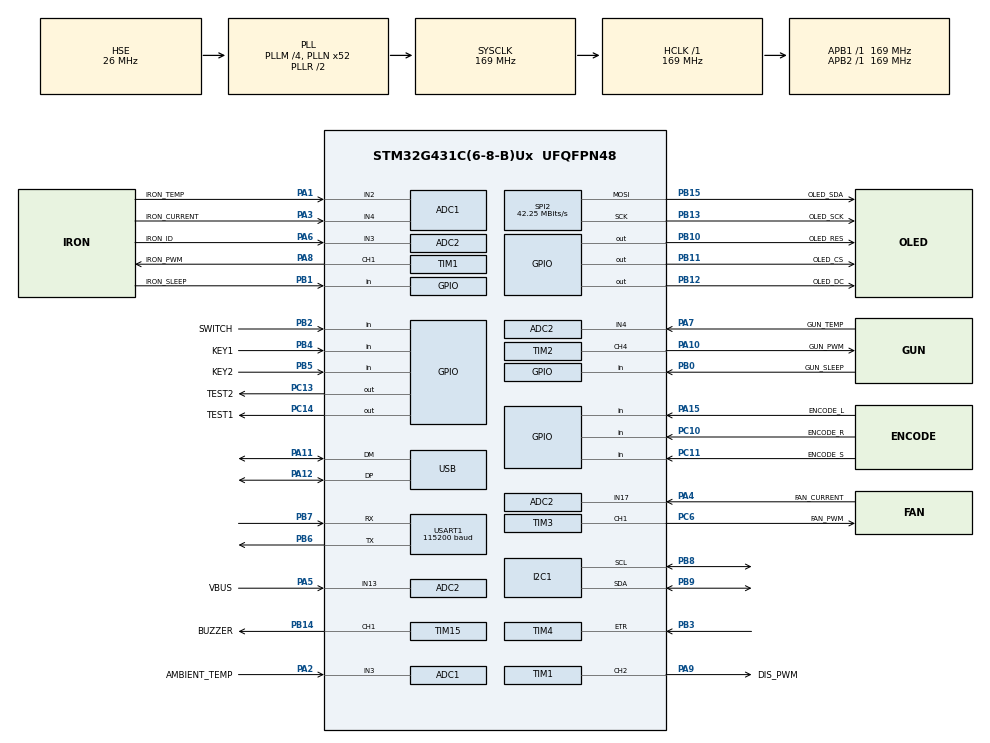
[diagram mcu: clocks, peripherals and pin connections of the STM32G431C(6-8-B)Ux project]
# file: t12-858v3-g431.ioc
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ADC1.EnableInjectedConversion=ENABLE
ADC1.EnableInjectedOversampling=DISABLE
ADC1.EnableRegularConversion=DISABLE
ADC1.ExternalTrigInjecConv=ADC_EXTERNALTRIGINJEC_T1_TRGO
ADC1.ExternalTrigInjecConvEdge=ADC_EXTERNALTRIGINJECCONV_EDGE_FALLING
ADC1.InjNumberOfConversion=2
ADC1.InjectedChannel-2\#ChannelInjectedConversion=ADC_CHANNEL_2
ADC1.InjectedChannel-3\#ChannelInjectedConversion=ADC_CHANNEL_4
ADC1.InjectedConvMode=None
ADC1.InjectedOffsetNumber-2\#ChannelInjectedConversion=ADC_OFFSET_NONE
ADC1.InjectedOffsetNumber-3\#ChannelInjectedConversion=ADC_OFFSET_NONE
ADC1.InjectedRank-2\#ChannelInjectedConversion=1
ADC1.InjectedRank-3\#ChannelInjectedConversion=2
ADC1.InjectedSamplingTime-2\#ChannelInjectedConversion=ADC_SAMPLETIME_12CYCLES_5
ADC1.InjectedSamplingTime-3\#ChannelInjectedConversion=ADC_SAMPLETIME_2CYCLES_5
ADC1.Rank2_Channel=ADC_CHANNEL_4
ADC1.injectedQueueMode=DISABLE
ADC1.master=1
ADC2.EnableInjectedConversion=ENABLE
ADC2.EnableRegularConversion=DISABLE
ADC2.ExternalTrigInjecConv=ADC_EXTERNALTRIGINJEC_T1_TRGO
ADC2.ExternalTrigInjecConvEdge=ADC_EXTERNALTRIGINJECCONV_EDGE_FALLING
ADC2.InjNumberOfConversion=2
ADC2.InjectedChannel-1\#ChannelInjectedConversion=ADC_CHANNEL_4
ADC2.InjectedChannel-2\#ChannelInjectedConversion=ADC_CHANNEL_17
ADC2.InjectedOffsetNumber-1\#ChannelInjectedConversion=ADC_OFFSET_NONE
ADC2.InjectedOffsetNumber-2\#ChannelInjectedConversion=ADC_OFFSET_NONE
ADC2.InjectedRank-1\#ChannelInjectedConversion=1
ADC2.InjectedRank-2\#ChannelInjectedConversion=2
ADC2.InjectedSamplingTime-1\#ChannelInjectedConversion=ADC_SAMPLETIME_12CYCLES_5
ADC2.InjectedSamplingTime-2\#ChannelInjectedConversion=ADC_SAMPLETIME_2CYCLES_5
ADC2.Rank2_Channel=ADC_CHANNEL_17
Dma.Request0=SPI2_TX
Dma.SPI2_TX.0.Direction=DMA_MEMORY_TO_PERIPH
Dma.SPI2_TX.0.EventEnable=DISABLE
Dma.SPI2_TX.0.Instance=DMA1_Channel1
Dma.SPI2_TX.0.MemDataAlignment=DMA_MDATAALIGN_BYTE
Dma.SPI2_TX.0.MemInc=DMA_MINC_ENABLE
Dma.SPI2_TX.0.Mode=DMA_NORMAL
Dma.SPI2_TX.0.PeriphDataAlignment=DMA_PDATAALIGN_BYTE
Dma.SPI2_TX.0.PeriphInc=DMA_PINC_DISABLE
Dma.SPI2_TX.0.Polarity=HAL_DMAMUX_REQ_GEN_RISING
Dma.SPI2_TX.0.Priority=DMA_PRIORITY_HIGH
Dma.SPI2_TX.0.RequestNumber=1
Dma.SPI2_TX.0.SignalID=NONE
Dma.SPI2_TX.0.SyncEnable=DISABLE
Dma.SPI2_TX.0.SyncPolarity=HAL_DMAMUX_SYNC_NO_EVENT
Dma.SPI2_TX.0.SyncRequestNumber=1
Dma.SPI2_TX.0.SyncSignalID=NONE
I2C1.Timing=0x408086C6
Mcu.Family=STM32G4
Mcu.Name=STM32G431C(6-8-B)Ux
Mcu.Package=UFQFPN48
NVIC.ADC1_2_IRQn=true\:0\:0\:false\:false\:true\:true\:true\:true
NVIC.DMA1_Channel1_IRQn=true\:0\:0\:false\:false\:true\:false\:true\:true
NVIC.PriorityGroup=NVIC_PRIORITYGROUP_4
NVIC.TIM3_IRQn=true\:0\:0\:false\:false\:true\:true\:true\:true
OPAMP1.PowerMode=OPAMP_POWERMODE_HIGHSPEED
PA1.GPIO_Label=IRON_TEMP
PA1.Signal=SharedAnalog_PA1
PA10.GPIO_Label=GUN_PWM
PA10.Signal=S_TIM2_CH4
PA11.Mode=Device
PA11.Signal=USB_DM
PA12.Mode=Device
PA12.Signal=USB_DP
PA13.Mode=Serial_Wire
PA13.Signal=SYS_JTMS-SWDIO
PA14.Mode=Serial_Wire
PA14.Signal=SYS_JTCK-SWCLK
PA15.GPIO_Label=ENCODE_L
PA15.GPIO_PuPd=GPIO_PULLUP
PA15.Signal=GPIO_Input
PA2.GPIO_Label=AMBIENT_TEMP
PA2.Mode=IN3-Single-Ended
PA2.Signal=ADC1_IN3
PA3.GPIO_Label=IRON_CURRENT
PA3.Mode=IN4-Single-Ended
PA3.Signal=ADC1_IN4
PA4.GPIO_Label=FAN_CURRENT
PA4.Mode=IN17-Single-Ended
PA4.Signal=ADC2_IN17
PA5.GPIO_Label=VBUS
PA5.Mode=IN13-Single-Ended
PA5.Signal=ADC2_IN13
PA6.GPIO_Label=IRON_ID
PA6.Mode=IN3-Single-Ended
PA6.Signal=ADC2_IN3
PA7.GPIO_Label=GUN_TEMP
PA7.Mode=IN4-Single-Ended
PA7.Signal=ADC2_IN4
PA8.GPIO_Label=IRON_PWM
PA8.GPIO_PuPd=GPIO_PULLDOWN
PA8.GPIO_Speed=GPIO_SPEED_FREQ_VERY_HIGH
PA8.Signal=S_TIM1_CH1
PA9.GPIO_Label=DIS_PWM
PA9.GPIO_PuPd=GPIO_PULLDOWN
PA9.GPIO_Speed=GPIO_SPEED_FREQ_VERY_HIGH
PA9.Signal=S_TIM1_CH2
PB0.GPIO_Label=GUN_SLEEP
PB0.GPIO_PuPd=GPIO_PULLUP
PB0.Signal=GPIO_Input
PB1.GPIO_Label=IRON_SLEEP
PB1.GPIO_PuPd=GPIO_PULLUP
PB1.Signal=GPIO_Input
PB10.GPIO_Label=OLED_RES
PB10.GPIO_PuPd=GPIO_PULLDOWN
PB10.Signal=GPIO_Output
PB11.GPIO_Label=OLED_CS
PB11.GPIO_PuPd=GPIO_PULLDOWN
PB11.Signal=GPIO_Output
PB12.GPIO_Label=OLED_DC
PB12.GPIO_PuPd=GPIO_PULLDOWN
PB12.GPIO_Speed=GPIO_SPEED_FREQ_VERY_HIGH
PB12.Signal=GPIO_Output
PB13.GPIO_Label=OLED_SCK
PB13.GPIO_Speed=GPIO_SPEED_FREQ_VERY_HIGH
PB13.Mode=TX_Only_Simplex_Unidirect_Master
PB13.Signal=SPI2_SCK
PB14.GPIO_Label=BUZZER
PB14.Signal=S_TIM15_CH1
PB15.GPIO_Label=OLED_SDA
PB15.GPIO_Speed=GPIO_SPEED_FREQ_VERY_HIGH
PB15.Mode=TX_Only_Simplex_Unidirect_Master
PB15.Signal=SPI2_MOSI
PB2.GPIO_Label=SWITCH
PB2.Signal=GPIO_Input
PB3.Signal=S_TIM4_ETR
PB4.GPIO_Label=KEY1
PB4.GPIO_PuPd=GPIO_PULLUP
PB4.Signal=GPIO_Input
PB5.GPIO_Label=KEY2
PB5.GPIO_PuPd=GPIO_PULLUP
PB5.Signal=GPIO_Input
PB6.Mode=Asynchronous
PB6.Signal=USART1_TX
PB7.Mode=Asynchronous
PB7.Signal=USART1_RX
PB8-BOOT0.GPIO_Pu=GPIO_PULLUP
PB8-BOOT0.GPIO_Speed=GPIO_SPEED_FREQ_VERY_HIGH
PB8-BOOT0.Mode=I2C
PB8-BOOT0.Signal=I2C1_SCL
PB9.GPIO_FM9=__NULL
PB9.GPIO_Pu=GPIO_PULLUP
PB9.GPIO_Speed=GPIO_SPEED_FREQ_VERY_HIGH
PB9.Mode=I2C
PB9.Signal=I2C1_SDA
PC10.GPIO_Label=ENCODE_R
PC10.GPIO_PuPd=GPIO_PULLUP
PC10.Signal=GPIO_Input
PC11.GPIO_Label=ENCODE_S
PC11.GPIO_PuPd=GPIO_PULLUP
PC11.Signal=GPIO_Input
PC13.GPIO_Label=TEST2
PC13.GPIO_PuPd=GPIO_PULLDOWN
PC13.Signal=GPIO_Output
PC14-OSC32_IN.GPIO_Label=TEST1
PC14-OSC32_IN.GPIO_PuPd=GPIO_PULLDOWN
PC14-OSC32_IN.Signal=GPIO_Output
PC6.GPIO_Label=FAN_PWM
PC6.Signal=S_TIM3_CH1
PF0-OSC_IN.Mode=HSE-External-Oscillator
PF0-OSC_IN.Signal=RCC_OSC_IN
PF1-OSC_OUT.Mode=HSE-External-Oscillator
PF1-OSC_OUT.Signal=RCC_OSC_OUT
ProjectManager.HeapSize=0x200
ProjectManager.StackSize=0x400
ProjectManager.TargetToolchain=Makefile
RCC.ADC12Freq_Value=169000000
RCC.AHBFreq_Value=169000000
RCC.APB1Freq_Value=169000000
RCC.APB1TimFreq_Value=169000000
RCC.APB2Freq_Value=169000000
RCC.APB2TimFreq_Value=169000000
RCC.CK48CLockSelection=RCC_USBCLKSOURCE_HSI48
RCC.CortexFreq_Value=169000000
RCC.EXTERNAL_CLOCK_VALUE=12288000
RCC.HCLKFreq_Value=169000000
RCC.HSE_VALUE=26000000
RCC.HSI48_VALUE=48000000
RCC.HSI_VALUE=16000000
RCC.LSE_VALUE=32768
RCC.PLLM=RCC_PLLM_DIV4
RCC.PLLN=52
RCC.PLLQ=RCC_PLLQ_DIV4
RCC.PLLSourceVirtual=RCC_PLLSOURCE_HSE
RCC.SYSCLKFreq_VALUE=169000000
RCC.SYSCLKSource=RCC_SYSCLKSOURCE_PLLCLK
RCC.USBFreq_Value=48000000
RCC.VCOOutputFreq_Value=338000000
SH.S_TIM15_CH1.0=TIM15_CH1,PWM Generation1 CH1
SH.S_TIM1_CH1.0=TIM1_CH1,PWM Generation1 CH1
SH.S_TIM1_CH2.0=TIM1_CH2,PWM Generation2 CH2
SH.S_TIM2_CH4.0=TIM2_CH4,PWM Generation4 CH4
SH.S_TIM3_CH1.0=TIM3_CH1,PWM Generation1 CH1
SH.S_TIM4_ETR.0=TIM4_ETR,ClockSourceETR_Mode2
SH.SharedAnalog_PA1.0=ADC1_IN2,IN2-Single-Ended
SH.SharedAnalog_PA1.1=OPAMP1_VINP,PGA_Internally_Connected
SPI2.BaudRatePrescaler=SPI_BAUDRATEPRESCALER_4
SPI2.CalculateBaudRate=42.25 MBits/s
SPI2.DataSize=SPI_DATASIZE_8BIT
SPI2.Direction=SPI_DIRECTION_2LINES
SPI2.Mode=SPI_MODE_MASTER
SPI2.NSSPMode=SPI_NSS_PULSE_DISABLE
SPI2.VirtualType=VM_MASTER
SYS.TrimmingMode=__NULL
SYS.VoltageScaling=SYSCFG_VREFBUF_VOLTAGE_SCALE2
TIM1.AutoReloadPreload=TIM_AUTORELOAD_PRELOAD_ENABLE
TIM1.Channel-PWM\ Generation1\ CH1=TIM_CHANNEL_1
TIM1.Channel-PWM\ Generation2\ CH2=TIM_CHANNEL_2
TIM1.Channel-PWM\ Generation3\ No\ Output=TIM_CHANNEL_3
TIM1.PeriodNoDither=4096-1
TIM1.Prescaler=1-1
TIM1.PulseNoDither_1=0
TIM1.PulseNoDither_2=0
TIM1.RepetitionCounter=0
TIM1.TIM_MasterOutputTrigger=TIM_TRGO_OC3REF
TIM15.Channel-PWM\ Generation1\ CH1=TIM_CHANNEL_1
TIM15.Channel-PWM\ Generation2\ No\ Output=TIM_CHANNEL_2
TIM15.PeriodNoDither=1000-1
TIM15.Prescaler=170-1
TIM2.Channel-PWM\ Generation4\ CH4=TIM_CHANNEL_4
TIM3.Channel-PWM\ Generation1\ CH1=TIM_CHANNEL_1
TIM3.PeriodNoDither=17000-1
TIM3.Prescaler=1-1
TIM3.PulseNoDither_1=50
TIM4.AutoReloadPreload=TIM_AUTORELOAD_PRELOAD_ENABLE
TIM4.Channel-PWM\ Generation1\ No\ Output=TIM_CHANNEL_1
TIM4.Dithering=Disable
TIM4.PeriodNoDither=10000-1
TIM4.Prescaler=170-1
TIM4.PulseNoDither_1=100
USART1.BaudRate=115200
USART1.VirtualMode-Asynchronous=VM_ASYNC
VP_ADC1_OPAMP_INTERNAL1.Mode=IN-OPAMP1
VP_SYS_VS_DBSignals.Mode=DisableDeadBatterySignals
VP_TIM15_VS_no_output2.Mode=PWM Generation2 No Output
VP_TIM1_VS_ClockSourceINT.Mode=Internal
VP_TIM1_VS_no_output3.Mode=PWM Generation3 No Output
VP_TIM2_VS_ClockSourceINT.Mode=Internal
VP_TIM3_VS_ClockSourceINT.Mode=Internal
VP_TIM4_VS_no_output1.Mode=PWM Generation1 No Output
VREF+.Mode=InternalMode
VREF+.Signal=VREFBUF_OUT
board=custom

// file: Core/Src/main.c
/* USER CODE BEGIN Header */
/**
  ******************************************************************************
  * @file           : main.c
  * @brief          : Main program body
  ******************************************************************************
  * @attention
  *
  * Copyright (c) 2024 STMicroelectronics.
  * All rights reserved.
  *
  * This software is licensed under terms that can be found in the LICENSE file
  * in the root directory of this software component.
  * If no LICENSE file comes with this software, it is provided AS-IS.
  *
  ******************************************************************************
  */
/* USER CODE END Header */
#include "main.h"
#include "adc.h"
#include "dma.h"
#include "i2c.h"
#include "opamp.h"
#include "spi.h"
#include "tim.h"
#include "usart.h"
#include "usb.h"
#include "gpio.h"

/* USER CODE BEGIN Includes */
#include "loop.h"
/* USER CODE END Includes */

void SystemClock_Config(void);

int main(void)
{

  /* MCU Configuration--------------------------------------------------------*/

  /* Reset of all peripherals, Initializes the Flash interface and the Systick. */
  HAL_Init();

  /* Configure the system clock */
  SystemClock_Config();

  /* Initialize all configured peripherals */
  MX_GPIO_Init();
  MX_DMA_Init();
  MX_ADC1_Init();
  MX_ADC2_Init();
  MX_I2C1_Init();
  MX_SPI2_Init();
  MX_TIM1_Init();
  MX_TIM2_Init();
  MX_USART1_UART_Init();
  MX_TIM15_Init();
  MX_TIM4_Init();
  MX_OPAMP1_Init();
  MX_TIM3_Init();
  MX_USB_PCD_Init();
  /* USER CODE BEGIN 2 */
    MY_Init();
  /* USER CODE END 2 */

  /* Infinite loop */
  while (1)
  {

    /* USER CODE BEGIN 3 */
    MY_Loop();
  }
  /* USER CODE END 3 */
}

void SystemClock_Config(void)
{
  RCC_OscInitTypeDef RCC_OscInitStruct = {0};
  RCC_ClkInitTypeDef RCC_ClkInitStruct = {0};

  /** Configure the main internal regulator output voltage
  */
  HAL_PWREx_ControlVoltageScaling(PWR_REGULATOR_VOLTAGE_SCALE1_BOOST);

  /** Initializes the RCC Oscillators according to the specified parameters
  * in the RCC_OscInitTypeDef structure.
  */
  RCC_OscInitStruct.OscillatorType = RCC_OSCILLATORTYPE_HSI48|RCC_OSCILLATORTYPE_HSE;
  RCC_OscInitStruct.HSEState = RCC_HSE_ON;
  RCC_OscInitStruct.HSI48State = RCC_HSI48_ON;
  RCC_OscInitStruct.PLL.PLLState = RCC_PLL_ON;
  RCC_OscInitStruct.PLL.PLLSource = RCC_PLLSOURCE_HSE;
  RCC_OscInitStruct.PLL.PLLM = RCC_PLLM_DIV4;
  RCC_OscInitStruct.PLL.PLLN = 52;
  RCC_OscInitStruct.PLL.PLLP = RCC_PLLP_DIV2;
  RCC_OscInitStruct.PLL.PLLQ = RCC_PLLQ_DIV4;
  RCC_OscInitStruct.PLL.PLLR = RCC_PLLR_DIV2;
  if (HAL_RCC_OscConfig(&RCC_OscInitStruct) != HAL_OK)
  {
    Error_Handler();
  }

  /** Initializes the CPU, AHB and APB buses clocks
  */
  RCC_ClkInitStruct.ClockType = RCC_CLOCKTYPE_HCLK|RCC_CLOCKTYPE_SYSCLK
                              |RCC_CLOCKTYPE_PCLK1|RCC_CLOCKTYPE_PCLK2;
  RCC_ClkInitStruct.SYSCLKSource = RCC_SYSCLKSOURCE_PLLCLK;
  RCC_ClkInitStruct.AHBCLKDivider = RCC_SYSCLK_DIV1;
  RCC_ClkInitStruct.APB1CLKDivider = RCC_HCLK_DIV1;
  RCC_ClkInitStruct.APB2CLKDivider = RCC_HCLK_DIV1;

  if (HAL_RCC_ClockConfig(&RCC_ClkInitStruct, FLASH_LATENCY_4) != HAL_OK)
  {
    Error_Handler();
  }
}

void Error_Handler(void)
{
  __disable_irq();
  while (1)
  {
  }
}
